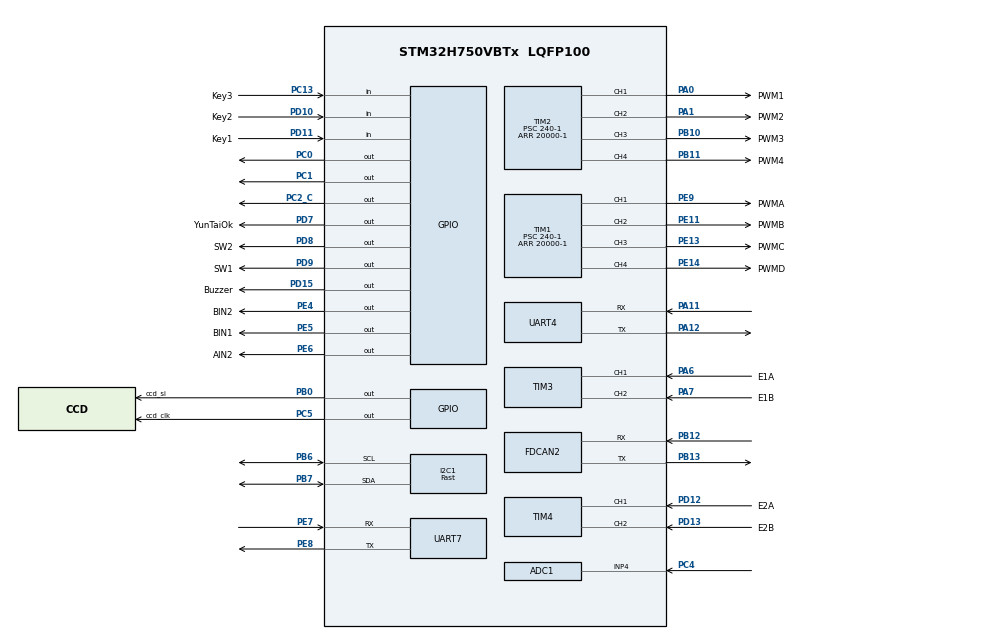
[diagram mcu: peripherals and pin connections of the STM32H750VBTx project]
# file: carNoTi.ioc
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ADC1.Channel-1\#ChannelRegularConversion=ADC_CHANNEL_4
ADC1.ContinuousConvMode=DISABLE
ADC1.NbrOfConversionFlag=1
ADC1.OffsetNumber-1\#ChannelRegularConversion=ADC_OFFSET_NONE
ADC1.OffsetSignedSaturation-1\#ChannelRegularConversion=DISABLE
ADC1.Rank-1\#ChannelRegularConversion=1
ADC1.Resolution=ADC_RESOLUTION_12B
ADC1.SamplingTime-1\#ChannelRegularConversion=ADC_SAMPLETIME_1CYCLE_5
ADC1.master=1
CORTEX_M7.default_mode_Activation=1
FDCAN2.CalculateBaudRateNominal=499999
FDCAN2.CalculateTimeBitNominal=2000
FDCAN2.CalculateTimeQuantumNominal=166.66666666666669
FDCAN2.NominalPrescaler=6
FDCAN2.NominalTimeSeg1=9
FDCAN2.NominalTimeSeg2=2
FDCAN2.RxBuffersNbr=4
FDCAN2.RxFifo0ElmtsNbr=4
FDCAN2.RxFifo1ElmtsNbr=4
FDCAN2.StdFiltersNbr=1
FDCAN2.TxBuffersNbr=4
FDCAN2.TxEventsNbr=4
FDCAN2.TxFifoQueueElmtsNbr=4
FREERTOS.Tasks01=defaultTask,24,128,StartDefaultTask,Default,NULL,Dynamic,NULL,NULL
FREERTOS.configUSE_NEWLIB_REENTRANT=1
I2C1.I2C_Speed_Mode=I2C_Fast
I2C1.Timing=0x00702787
Mcu.Family=STM32H7
Mcu.Name=STM32H750VBTx
Mcu.Package=LQFP100
NVIC.FDCAN2_IT0_IRQn=true\:5\:0\:false\:false\:true\:true\:true\:true\:true
NVIC.PriorityGroup=NVIC_PRIORITYGROUP_4
NVIC.TIM5_IRQn=true\:15\:0\:false\:false\:true\:false\:false\:true\:true
NVIC.TIM8_UP_TIM13_IRQn=true\:5\:0\:false\:false\:true\:true\:true\:true\:true
NVIC.TimeBase=TIM5_IRQn
NVIC.TimeBaseIP=TIM5
NVIC.UART4_IRQn=true\:5\:0\:false\:false\:true\:true\:true\:true\:true
NVIC.UART7_IRQn=true\:5\:0\:false\:false\:true\:true\:true\:true\:true
PA0.GPIO_Label=PWM1
PA0.Signal=S_TIM2_CH1_ETR
PA1.GPIO_Label=PWM2
PA1.Signal=S_TIM2_CH2
PA11.Mode=Asynchronous
PA11.Signal=UART4_RX
PA12.Mode=Asynchronous
PA12.Signal=UART4_TX
PA13\ (JTMS/SWDIO).Mode=Serial_Wire
PA13\ (JTMS/SWDIO).Signal=DEBUG_JTMS-SWDIO
PA14\ (JTCK/SWCLK).Mode=Serial_Wire
PA14\ (JTCK/SWCLK).Signal=DEBUG_JTCK-SWCLK
PA6.GPIO_Label=E1A
PA6.Signal=S_TIM3_CH1
PA7.GPIO_Label=E1B
PA7.Signal=S_TIM3_CH2
PB0.GPIO_Label=ccd_si
PB0.Signal=GPIO_Output
PB10.GPIO_Label=PWM3
PB10.Signal=S_TIM2_CH3
PB11.GPIO_Label=PWM4
PB11.Signal=S_TIM2_CH4
PB12.Mode=FDCAN_Activate
PB12.Signal=FDCAN2_RX
PB13.Mode=FDCAN_Activate
PB13.Signal=FDCAN2_TX
PB6.Mode=I2C
PB6.Signal=I2C1_SCL
PB7.Mode=I2C
PB7.Signal=I2C1_SDA
PC0.Signal=GPIO_Output
PC1.Signal=GPIO_Output
PC13.GPIO_Label=Key3
PC13.GPIO_PuPd=GPIO_PULLUP
PC13.Signal=GPIO_Input
PC14-OSC32_IN\ (OSC32_IN).Mode=LSE-External-Oscillator
PC14-OSC32_IN\ (OSC32_IN).Signal=RCC_OSC32_IN
PC15-OSC32_OUT\ (OSC32_OUT).Mode=LSE-External-Oscillator
PC15-OSC32_OUT\ (OSC32_OUT).Signal=RCC_OSC32_OUT
PC2_C.Signal=GPIO_Output
PC4.Signal=ADCx_INP4
PC5.GPIO_Label=ccd_clk
PC5.Signal=GPIO_Output
PD10.GPIO_Label=Key2
PD10.GPIO_PuPd=GPIO_PULLUP
PD10.Signal=GPIO_Input
PD11.GPIO_Label=Key1
PD11.GPIO_PuPd=GPIO_PULLUP
PD11.Signal=GPIO_Input
PD12.GPIO_Label=E2A
PD12.Signal=S_TIM4_CH1
PD13.GPIO_Label=E2B
PD13.Signal=S_TIM4_CH2
PD15.GPIO_Label=Buzzer
PD15.PinState=GPIO_PIN_SET
PD15.Signal=GPIO_Output
PD7.GPIO_Label=YunTaiOk
PD7.Signal=GPIO_Output
PD8.GPIO_Label=SW2
PD8.Signal=GPIO_Output
PD9.GPIO_Label=SW1
PD9.Signal=GPIO_Output
PE11.GPIO_Label=PWMB
PE11.Signal=S_TIM1_CH2
PE13.GPIO_Label=PWMC
PE13.Signal=S_TIM1_CH3
PE14.GPIO_Label=PWMD
PE14.Signal=S_TIM1_CH4
PE4.GPIO_Label=BIN2
PE4.Signal=GPIO_Output
PE5.GPIO_Label=BIN1
PE5.Signal=GPIO_Output
PE6.GPIO_Label=AIN2
PE6.Signal=GPIO_Output
PE7.Mode=Asynchronous
PE7.Signal=UART7_RX
PE8.Mode=Asynchronous
PE8.Signal=UART7_TX
PE9.GPIO_Label=PWMA
PE9.Signal=S_TIM1_CH1
PH0-OSC_IN\ (PH0).Mode=HSE-External-Oscillator
PH0-OSC_IN\ (PH0).Signal=RCC_OSC_IN
PH1-OSC_OUT\ (PH1).Mode=HSE-External-Oscillator
PH1-OSC_OUT\ (PH1).Signal=RCC_OSC_OUT
ProjectManager.HeapSize=0x200
ProjectManager.StackSize=0x400
ProjectManager.TargetToolchain=STM32CubeIDE
RCC.ADCFreq_Value=90000000
RCC.APB1Freq_Value=120000000
RCC.APB2Freq_Value=120000000
RCC.APB3Freq_Value=120000000
RCC.APB4Freq_Value=120000000
RCC.CortexFreq_Value=480000000
RCC.D1PPRE=RCC_APB3_DIV2
RCC.D2PPRE1=RCC_APB1_DIV2
RCC.D2PPRE2=RCC_APB2_DIV2
RCC.D3PPRE=RCC_APB4_DIV2
RCC.DIVM1=5
RCC.DIVM2=5
RCC.DIVM3=2
RCC.DIVN1=192
RCC.DIVN2=36
RCC.DIVN3=12
RCC.DIVQ1=4
RCC.DIVQ2=5
RCC.DIVR1=4
RCC.FDCANCLockSelection=RCC_FDCANCLKSOURCE_PLL2
RCC.HCLKFreq_Value=240000000
RCC.HPRE=RCC_HCLK_DIV2
RCC.I2C123CLockSelection=RCC_I2C123CLKSOURCE_PLL3
RCC.PLL2FRACN=0
RCC.PLL3FRACN=0
RCC.PLLFRACN=0
RCC.PLLSourceVirtual=RCC_PLLSOURCE_HSE
RCC.SYSCLKFreq_VALUE=480000000
RCC.SYSCLKSource=RCC_SYSCLKSOURCE_PLLCLK
RCC.USART16CLockSelection=RCC_USART16CLKSOURCE_PLL3
RCC.USBFreq_Value=240000000
SH.ADCx_INP4.0=ADC1_INP4,IN4-Single-Ended
SH.S_TIM1_CH1.0=TIM1_CH1,PWM Generation1 CH1
SH.S_TIM1_CH2.0=TIM1_CH2,PWM Generation2 CH2
SH.S_TIM1_CH3.0=TIM1_CH3,PWM Generation3 CH3
SH.S_TIM1_CH4.0=TIM1_CH4,PWM Generation4 CH4
SH.S_TIM2_CH1_ETR.0=TIM2_CH1,PWM Generation1 CH1
SH.S_TIM2_CH2.0=TIM2_CH2,PWM Generation2 CH2
SH.S_TIM2_CH3.0=TIM2_CH3,PWM Generation3 CH3
SH.S_TIM2_CH4.0=TIM2_CH4,PWM Generation4 CH4
SH.S_TIM3_CH1.0=TIM3_CH1,Encoder_Interface
SH.S_TIM3_CH2.0=TIM3_CH2,Encoder_Interface
SH.S_TIM4_CH1.0=TIM4_CH1,Encoder_Interface
SH.S_TIM4_CH2.0=TIM4_CH2,Encoder_Interface
TIM1.Channel-PWM\ Generation1\ CH1=TIM_CHANNEL_1
TIM1.Channel-PWM\ Generation2\ CH2=TIM_CHANNEL_2
TIM1.Channel-PWM\ Generation3\ CH3=TIM_CHANNEL_3
TIM1.Channel-PWM\ Generation4\ CH4=TIM_CHANNEL_4
TIM1.Period=20000-1
TIM1.Prescaler=240-1
TIM2.Channel-PWM\ Generation1\ CH1=TIM_CHANNEL_1
TIM2.Channel-PWM\ Generation2\ CH2=TIM_CHANNEL_2
TIM2.Channel-PWM\ Generation3\ CH3=TIM_CHANNEL_3
TIM2.Channel-PWM\ Generation4\ CH4=TIM_CHANNEL_4
TIM2.Period=20000-1
TIM2.Prescaler=240-1
TIM8.Period=5000-1
TIM8.Prescaler=240-1
VP_FREERTOS_VS_CMSIS_V2.Mode=CMSIS_V2
VP_MEMORYMAP_VS_MEMORYMAP.Mode=CurAppReg
VP_SYS_VS_tim5.Mode=TIM5
VP_TIM8_VS_ClockSourceINT.Mode=Internal
board=custom

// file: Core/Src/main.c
/* USER CODE BEGIN Header */
/**
  ******************************************************************************
  * @file           : main.c
  * @brief          : Main program body
  ******************************************************************************
  * @attention
  *
  * Copyright (c) 2025 STMicroelectronics.
  * All rights reserved.
  *
  * This software is licensed under terms that can be found in the LICENSE file
  * in the root directory of this software component.
  * If no LICENSE file comes with this software, it is provided AS-IS.
  *
  ******************************************************************************
  */
/* USER CODE END Header */
#include "main.h"
#include "cmsis_os.h"
#include "adc.h"
#include "fdcan.h"
#include "i2c.h"
#include "memorymap.h"
#include "tim.h"
#include "usart.h"
#include "gpio.h"

void SystemClock_Config(void);
void PeriphCommonClock_Config(void);
static void MPU_Config(void);
void MX_FREERTOS_Init(void);

int main(void)
{

  /* MPU Configuration--------------------------------------------------------*/
  MPU_Config();

  /* MCU Configuration--------------------------------------------------------*/

  /* Reset of all peripherals, Initializes the Flash interface and the Systick. */
  HAL_Init();

  /* Configure the system clock */
  SystemClock_Config();

  /* Configure the peripherals common clocks */
  PeriphCommonClock_Config();

  /* Initialize all configured peripherals */
  MX_GPIO_Init();
  MX_TIM1_Init();
  MX_I2C1_Init();
  MX_TIM2_Init();
  MX_TIM3_Init();
  MX_TIM4_Init();
  MX_TIM8_Init();
  MX_ADC1_Init();
  MX_FDCAN2_Init();
  MX_UART7_Init();
  MX_UART4_Init();

  /* Init scheduler */
  osKernelInitialize();

  /* Call init function for freertos objects (in cmsis_os2.c) */
  MX_FREERTOS_Init();

  /* Start scheduler */
  osKernelStart();

  /* We should never get here as control is now taken by the scheduler */

  /* Infinite loop */
  while (1)
  {

  }
}

void SystemClock_Config(void)
{
  RCC_OscInitTypeDef RCC_OscInitStruct = {0};
  RCC_ClkInitTypeDef RCC_ClkInitStruct = {0};

  /** Supply configuration update enable
  */
  HAL_PWREx_ConfigSupply(PWR_LDO_SUPPLY);

  /** Configure the main internal regulator output voltage
  */
  __HAL_PWR_VOLTAGESCALING_CONFIG(PWR_REGULATOR_VOLTAGE_SCALE0);

  while(!__HAL_PWR_GET_FLAG(PWR_FLAG_VOSRDY)) {}

  /** Initializes the RCC Oscillators according to the specified parameters
  * in the RCC_OscInitTypeDef structure.
  */
  RCC_OscInitStruct.OscillatorType = RCC_OSCILLATORTYPE_HSE;
  RCC_OscInitStruct.HSEState = RCC_HSE_ON;
  RCC_OscInitStruct.PLL.PLLState = RCC_PLL_ON;
  RCC_OscInitStruct.PLL.PLLSource = RCC_PLLSOURCE_HSE;
  RCC_OscInitStruct.PLL.PLLM = 5;
  RCC_OscInitStruct.PLL.PLLN = 192;
  RCC_OscInitStruct.PLL.PLLP = 2;
  RCC_OscInitStruct.PLL.PLLQ = 4;
  RCC_OscInitStruct.PLL.PLLR = 4;
  RCC_OscInitStruct.PLL.PLLRGE = RCC_PLL1VCIRANGE_2;
  RCC_OscInitStruct.PLL.PLLVCOSEL = RCC_PLL1VCOWIDE;
  RCC_OscInitStruct.PLL.PLLFRACN = 0;
  if (HAL_RCC_OscConfig(&RCC_OscInitStruct) != HAL_OK)
  {
    Error_Handler();
  }

  /** Initializes the CPU, AHB and APB buses clocks
  */
  RCC_ClkInitStruct.ClockType = RCC_CLOCKTYPE_HCLK|RCC_CLOCKTYPE_SYSCLK
                              |RCC_CLOCKTYPE_PCLK1|RCC_CLOCKTYPE_PCLK2
                              |RCC_CLOCKTYPE_D3PCLK1|RCC_CLOCKTYPE_D1PCLK1;
  RCC_ClkInitStruct.SYSCLKSource = RCC_SYSCLKSOURCE_PLLCLK;
  RCC_ClkInitStruct.SYSCLKDivider = RCC_SYSCLK_DIV1;
  RCC_ClkInitStruct.AHBCLKDivider = RCC_HCLK_DIV2;
  RCC_ClkInitStruct.APB3CLKDivider = RCC_APB3_DIV2;
  RCC_ClkInitStruct.APB1CLKDivider = RCC_APB1_DIV2;
  RCC_ClkInitStruct.APB2CLKDivider = RCC_APB2_DIV2;
  RCC_ClkInitStruct.APB4CLKDivider = RCC_APB4_DIV2;

  if (HAL_RCC_ClockConfig(&RCC_ClkInitStruct, FLASH_LATENCY_4) != HAL_OK)
  {
    Error_Handler();
  }
}

void PeriphCommonClock_Config(void)
{
  RCC_PeriphCLKInitTypeDef PeriphClkInitStruct = {0};

  /** Initializes the peripherals clock
  */
  PeriphClkInitStruct.PeriphClockSelection = RCC_PERIPHCLK_ADC|RCC_PERIPHCLK_FDCAN;
  PeriphClkInitStruct.PLL2.PLL2M = 5;
  PeriphClkInitStruct.PLL2.PLL2N = 36;
  PeriphClkInitStruct.PLL2.PLL2P = 2;
  PeriphClkInitStruct.PLL2.PLL2Q = 5;
  PeriphClkInitStruct.PLL2.PLL2R = 2;
  PeriphClkInitStruct.PLL2.PLL2RGE = RCC_PLL2VCIRANGE_2;
  PeriphClkInitStruct.PLL2.PLL2VCOSEL = RCC_PLL2VCOMEDIUM;
  PeriphClkInitStruct.PLL2.PLL2FRACN = 0;
  PeriphClkInitStruct.FdcanClockSelection = RCC_FDCANCLKSOURCE_PLL2;
  PeriphClkInitStruct.AdcClockSelection = RCC_ADCCLKSOURCE_PLL2;
  if (HAL_RCCEx_PeriphCLKConfig(&PeriphClkInitStruct) != HAL_OK)
  {
    Error_Handler();
  }
}

 /* MPU Configuration */

void MPU_Config(void)
{
  MPU_Region_InitTypeDef MPU_InitStruct = {0};

  /* Disables the MPU */
  HAL_MPU_Disable();

  /** Initializes and configures the Region and the memory to be protected
  */
  MPU_InitStruct.Enable = MPU_REGION_ENABLE;
  MPU_InitStruct.Number = MPU_REGION_NUMBER0;
  MPU_InitStruct.BaseAddress = 0x0;
  MPU_InitStruct.Size = MPU_REGION_SIZE_4GB;
  MPU_InitStruct.SubRegionDisable = 0x87;
  MPU_InitStruct.TypeExtField = MPU_TEX_LEVEL0;
  MPU_InitStruct.AccessPermission = MPU_REGION_NO_ACCESS;
  MPU_InitStruct.DisableExec = MPU_INSTRUCTION_ACCESS_DISABLE;
  MPU_InitStruct.IsShareable = MPU_ACCESS_SHAREABLE;
  MPU_InitStruct.IsCacheable = MPU_ACCESS_NOT_CACHEABLE;
  MPU_InitStruct.IsBufferable = MPU_ACCESS_NOT_BUFFERABLE;

  HAL_MPU_ConfigRegion(&MPU_InitStruct);
  /* Enables the MPU */
  HAL_MPU_Enable(MPU_PRIVILEGED_DEFAULT);

}

void HAL_TIM_PeriodElapsedCallback(TIM_HandleTypeDef *htim)
{
  if (htim->Instance == TIM5)
  {
    HAL_IncTick();
  }
}

void Error_Handler(void)
{
  __disable_irq();
  while (1)
  {
  }
}

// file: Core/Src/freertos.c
/* USER CODE BEGIN Header */
/**
  ******************************************************************************
  * File Name          : freertos.c
  * Description        : Code for freertos applications
  ******************************************************************************
  * @attention
  *
  * Copyright (c) 2025 STMicroelectronics.
  * All rights reserved.
  *
  * This software is licensed under terms that can be found in the LICENSE file
  * in the root directory of this software component.
  * If no LICENSE file comes with this software, it is provided AS-IS.
  *
  ******************************************************************************
  */
/* USER CODE END Header */

#include "FreeRTOS.h"
#include "task.h"
#include "main.h"
#include "cmsis_os.h"

/* USER CODE BEGIN Includes */
#include "entry.h"
/* USER CODE END Includes */

/* Definitions for defaultTask */
osThreadId_t defaultTaskHandle;
const osThreadAttr_t defaultTask_attributes = {
  .name = "defaultTask",
  .stack_size = 128 * 4,
  .priority = (osPriority_t) osPriorityNormal,
};

void StartDefaultTask(void *argument);

void MX_FREERTOS_Init(void); /* (MISRA C 2004 rule 8.1) */

void MX_FREERTOS_Init(void) {

  /* USER CODE BEGIN RTOS_QUEUES */
  xRecvQueue = xQueueCreate(2, sizeof(uint8_t)*64);
  /* add queues, ... */
  /* USER CODE END RTOS_QUEUES */

  /* Create the thread(s) */
  /* creation of defaultTask */
  defaultTaskHandle = osThreadNew(StartDefaultTask, NULL, &defaultTask_attributes);

  /* USER CODE BEGIN RTOS_THREADS */
  xTaskCreate(setupTask,"setupTask",128,NULL,3,NULL);
  /* add threads, ... */
  /* USER CODE END RTOS_THREADS */

}

void StartDefaultTask(void *argument)
{
  for(;;)
  {
    osDelay(1);
  }
}
